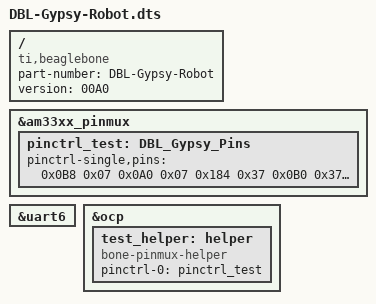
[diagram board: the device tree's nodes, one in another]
/*  
* Copyright (C) 2012 Texas Instruments Incorporated - http://www.ti.com/
*
* This program is free software; you can redistribute it and/or modify
* it under the terms of the GNU General Purpose License Version 2 as
* published by the Free Software Foundation
*
* Original from: github.com/jadonk/validation-scripts/blob/master/test-capemgr/ 
*
* Modified by Derek Molloy for the example on www.derekmolloy.ie
* that maps GPIO pins for the example
*/

/dts-v1/;
/plugin/;

/{
	compatible = "ti,beaglebone", "ti,beaglebone-black";
	part-number = "DBL-Gypsy-Robot";
	version = "00A0";

	fragment@0 {
		target = <&am33xx_pinmux>;
            
		__overlay__ {
			pinctrl_test: DBL_Gypsy_Pins {
				pinctrl-single,pins = <
					
					0x0B8 0x07	/* P8_39	76	OUTPUT	MODE7			- LED1 Output */
					0x0A0 0x07	/* P8_45	70	OUTPUT	MODE7			- LED2 Output */
					
					0x184 0x37	/* P9_24	15	INPUT	MODE7	pullup	- Start Button */
					0x0B0 0x37	/* P8_41	74	INPUT	MODE7	pullup	- Pause Button */
					
					0x0C0 0x0C	/* P8_37	78	OUTPUT	MODE4			- Motor Serial TX */
					
					0x0BC 0x2f	/* P8_40	77	INPUT	MODE7	none	- Encoder Left A */
					0x0B4 0x2f	/* P8_42	75	INPUT	MODE7	none	- Encoder Left B */
					0x0AC 0x2f	/* P8_44	73	INPUT	MODE7	none	- Encoder Right A */
					0x0A4 0x2f	/* P8_46	71	INPUT	MODE7	none	- Encoder Right B */
					       
					/* OUTPUT  GPIO(mode7) 0x07 pulldown, 0x17 pullup, 0x?f no pullup/down */
					/* INPUT   GPIO(mode7) 0x27 pulldown, 0x37 pullup, 0x?f no pullup/down */

				>;
			};
		};
	};
	
	fragment@1{
		target = <&uart6>;
		__overlay__ {
			status = "okay";
		};
	};
	
	fragment@2 {
		target = <&ocp>;
		__overlay__ {
			test_helper: helper {
				compatible = "bone-pinmux-helper";
				pinctrl-names = "default";
				pinctrl-0 = <&pinctrl_test>;
				status = "okay";
			};
		};
	};
};
